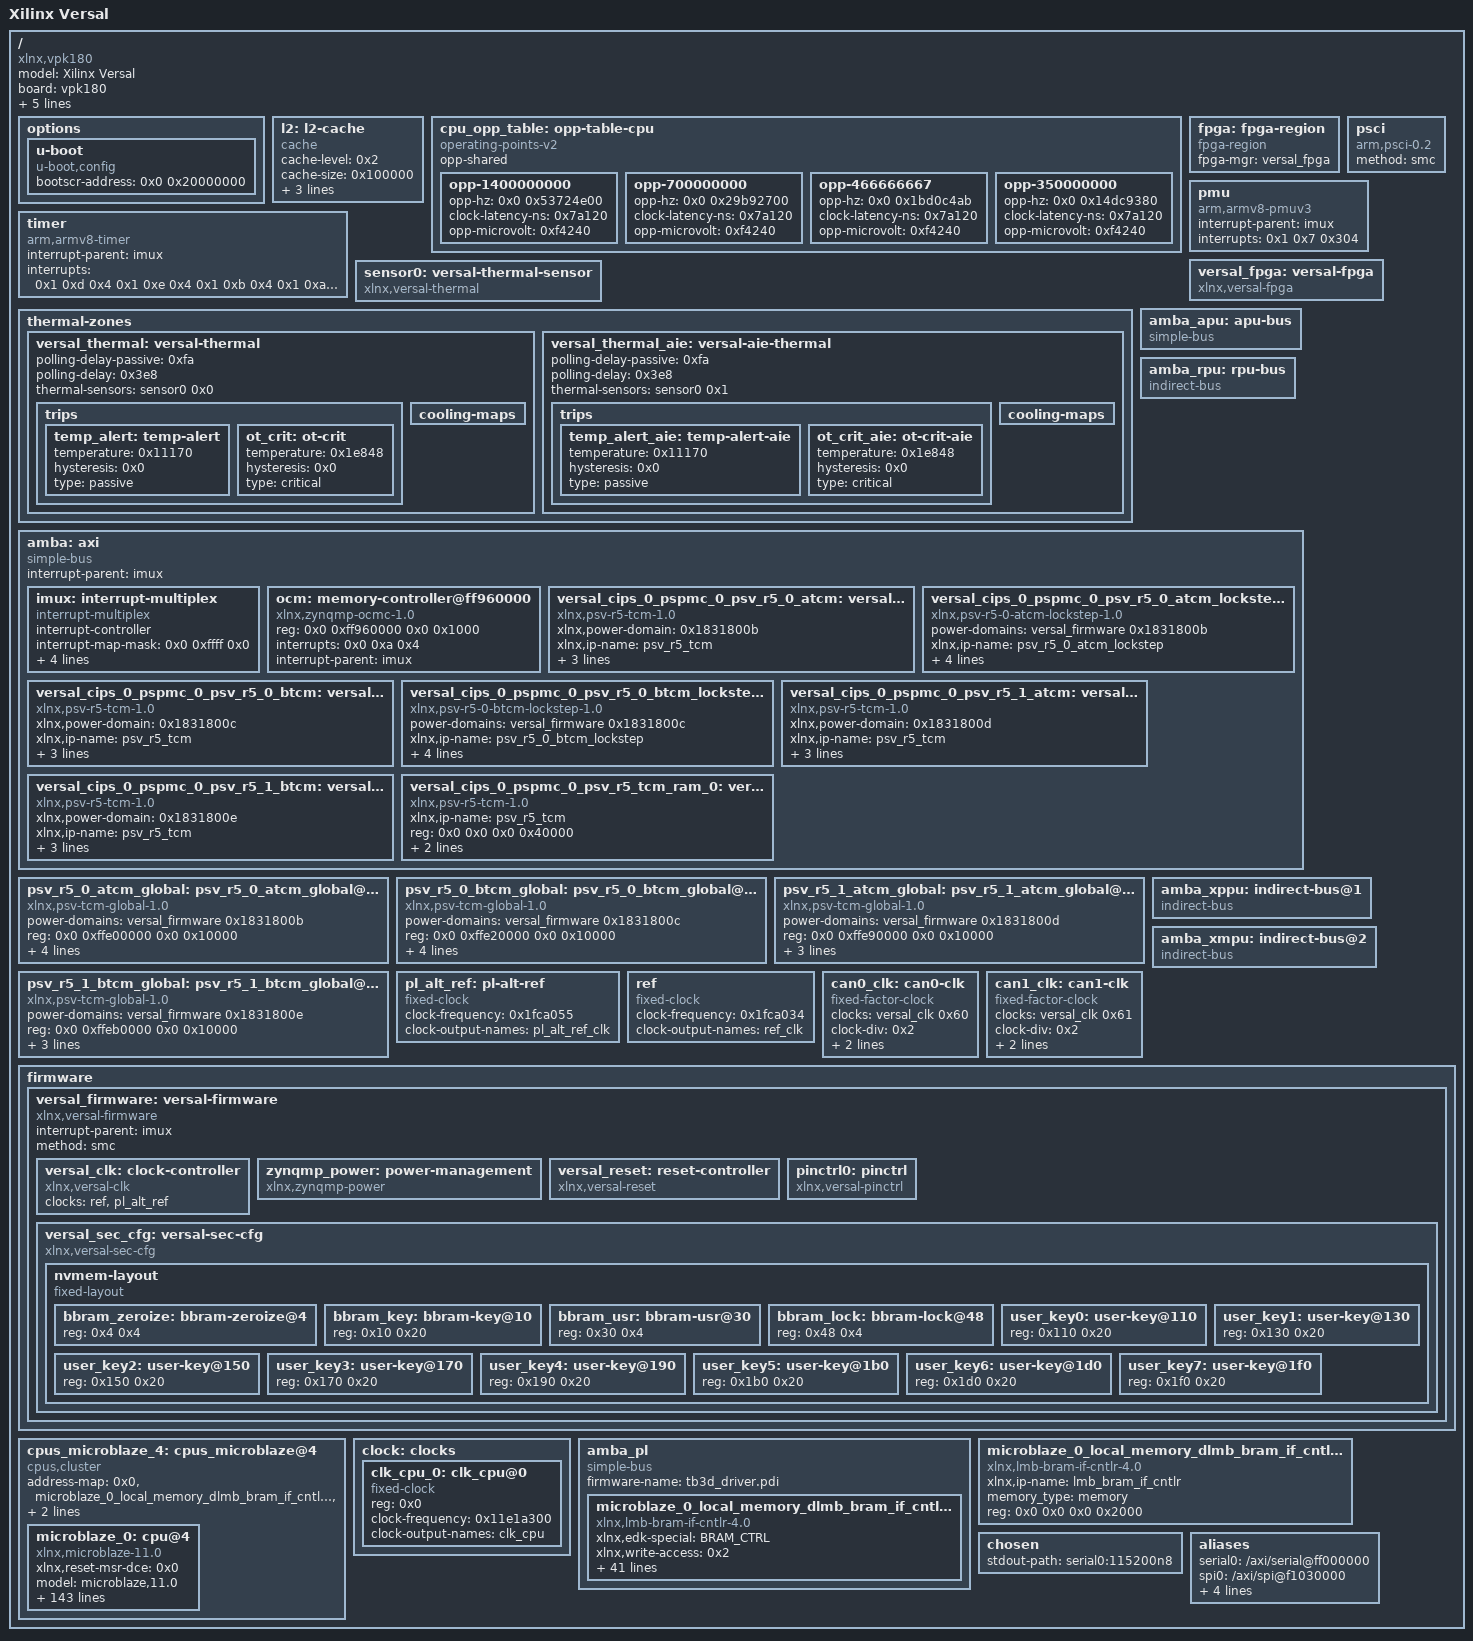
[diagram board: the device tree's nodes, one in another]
/dts-v1/;
/ {
        compatible = "xlnx,vpk180";
        #address-cells = <0x2>;
        #size-cells = <0x2>;
        model = "Xilinx Versal";
        board = "vpk180";
        device_id = "xcvp1802";
        slrcount = <0x4>;
        family = "Versal";
        speed_grade = "2MP";
        pruned-sdt = <0x1>;

        options {

                u-boot {
                        compatible = "u-boot,config";
                        bootscr-address = <0x0 0x20000000>;
                };
        };

        l2: l2-cache {
                phandle = <0x87>;
                compatible = "cache";
                cache-level = <0x2>;
                cache-size = <0x100000>;
                cache-line-size = <0x40>;
                cache-sets = <0x1000>;
                cache-unified;
        };

        cpu_opp_table: opp-table-cpu {
                phandle = <0x84>;
                compatible = "operating-points-v2";
                opp-shared;

                opp-1400000000 {
                        opp-hz = <0x0 0x53724e00>;
                        clock-latency-ns = <0x7a120>;
                        opp-microvolt = <0xf4240>;
                };

                opp-700000000 {
                        opp-hz = <0x0 0x29b92700>;
                        clock-latency-ns = <0x7a120>;
                        opp-microvolt = <0xf4240>;
                };

                opp-466666667 {
                        opp-hz = <0x0 0x1bd0c4ab>;
                        clock-latency-ns = <0x7a120>;
                        opp-microvolt = <0xf4240>;
                };

                opp-350000000 {
                        opp-hz = <0x0 0x14dc9380>;
                        clock-latency-ns = <0x7a120>;
                        opp-microvolt = <0xf4240>;
                };
        };

        fpga: fpga-region {
                phandle = <0xb6>;
                compatible = "fpga-region";
                fpga-mgr = <&versal_fpga>;
                #address-cells = <0x2>;
                #size-cells = <0x2>;
        };

        psci: psci {
                phandle = <0xb7>;
                compatible = "arm,psci-0.2";
                method = "smc";
        };

        pmu {
                compatible = "arm,armv8-pmuv3";
                interrupt-parent = <&imux>;
                interrupts = <0x1 0x7 0x304>;
        };

        timer: timer {
                phandle = <0xb8>;
                compatible = "arm,armv8-timer";
                interrupt-parent = <&imux>;
                interrupts = <0x1 0xd 0x4 0x1 0xe 0x4 0x1 0xb 0x4 0x1 0xa 0x4>;
        };

        versal_fpga: versal-fpga {
                phandle = <0x9d>;
                compatible = "xlnx,versal-fpga";
        };

        sensor0: versal-thermal-sensor {
                phandle = <0x9f>;
                compatible = "xlnx,versal-thermal";
                #thermal-sensor-cells = <0x1>;
                io-channel-names = "sysmon-temp-channel";
        };

        thermal-zones {

                versal_thermal: versal-thermal {
                        phandle = <0xb9>;
                        polling-delay-passive = <0xfa>;
                        polling-delay = <0x3e8>;
                        thermal-sensors = <&sensor0 0x0>;

                        trips {

                                temp_alert: temp-alert {
                                        phandle = <0xba>;
                                        temperature = <0x11170>;
                                        hysteresis = <0x0>;
                                        type = "passive";
                                };

                                ot_crit: ot-crit {
                                        phandle = <0xbb>;
                                        temperature = <0x1e848>;
                                        hysteresis = <0x0>;
                                        type = "critical";
                                };
                        };

                        cooling-maps {
                        };
                };

                versal_thermal_aie: versal-aie-thermal {
                        phandle = <0xbc>;
                        polling-delay-passive = <0xfa>;
                        polling-delay = <0x3e8>;
                        thermal-sensors = <&sensor0 0x1>;

                        trips {

                                temp_alert_aie: temp-alert-aie {
                                        phandle = <0xbd>;
                                        temperature = <0x11170>;
                                        hysteresis = <0x0>;
                                        type = "passive";
                                };

                                ot_crit_aie: ot-crit-aie {
                                        phandle = <0xbe>;
                                        temperature = <0x1e848>;
                                        hysteresis = <0x0>;
                                        type = "critical";
                                };
                        };

                        cooling-maps {
                        };
                };
        };

        amba_apu: apu-bus {
                phandle = <0x2>;
                compatible = "simple-bus";
                #address-cells = <0x2>;
                #size-cells = <0x2>;
                ranges;
                bootph-all;
        };

        amba_rpu: rpu-bus {
                phandle = <0x92>;
                compatible = "indirect-bus";
                #address-cells = <0x2>;
                #size-cells = <0x2>;
                ranges;
                bootph-all;
        };

        amba: axi {
                phandle = <0x1>;
                compatible = "simple-bus";
                #address-cells = <0x2>;
                #size-cells = <0x2>;
                ranges;
                interrupt-parent = <&imux>;
                bootph-all;

                imux: interrupt-multiplex {
                        phandle = <0x9e>;
                        compatible = "interrupt-multiplex";
                        #address-cells = <0x0>;
                        #interrupt-cells = <0x3>;
                        interrupt-controller;
                        interrupt-map-mask = <0x0 0xffff 0x0>;
                        interrupt-map = <0x58 0x0 0x15 &amba 0x0>,
                         <0x0 0x58 0x0 &psv_r5_1_btcm_global 0x4>,
                         <0x96 0x0 0x14 &amba 0x0>,
                         <0x83 0x4 0x0 &cpu_opp_table 0x0>;
                };

                ocm: memory-controller@ff960000 {
                        phandle = <0xc9>;
                        compatible = "xlnx,zynqmp-ocmc-1.0";
                        reg = <0x0 0xff960000 0x0 0x1000>;
                        interrupts = <0x0 0xa 0x4>;
                        interrupt-parent = <&imux>;
                };

                versal_cips_0_pspmc_0_psv_r5_0_atcm: versal_cips_0_pspmc_0_psv_r5_0_atcm@0 {
                        phandle = <0x93>;
                        xlnx,power-domain = <0x1831800b>;
                        compatible = "xlnx,psv-r5-tcm-1.0";
                        status = "okay";
                        xlnx,ip-name = "psv_r5_tcm";
                        xlnx,bank-size = <0x10000>;
                        reg = <0x0 0x0 0x0 0x10000>;
                        xlnx,name = "versal_cips_0_pspmc_0_psv_r5_0_atcm";
                };

                versal_cips_0_pspmc_0_psv_r5_0_atcm_lockstep: versal_cips_0_pspmc_0_psv_r5_0_atcm_lockstep@ffe10000 {
                        phandle = <0x148>;
                        compatible = "xlnx,psv-r5-0-atcm-lockstep-1.0", "mmio-sram";
                        status = "okay";
                        power-domains = <&versal_firmware 0x1831800b>;
                        xlnx,ip-name = "psv_r5_0_atcm_lockstep";
                        xlnx,is-hierarchy;
                        reg = <0x0 0xffe10000 0x0 0x10000>;
                        xlnx,name = "versal_cips_0_pspmc_0_psv_r5_0_atcm_lockstep";
                };

                versal_cips_0_pspmc_0_psv_r5_0_btcm: versal_cips_0_pspmc_0_psv_r5_0_btcm@20000 {
                        phandle = <0x95>;
                        xlnx,power-domain = <0x1831800c>;
                        compatible = "xlnx,psv-r5-tcm-1.0";
                        status = "okay";
                        xlnx,ip-name = "psv_r5_tcm";
                        xlnx,bank-size = <0x10000>;
                        reg = <0x0 0x20000 0x0 0x10000>;
                        xlnx,name = "versal_cips_0_pspmc_0_psv_r5_0_btcm";
                };

                versal_cips_0_pspmc_0_psv_r5_0_btcm_lockstep: versal_cips_0_pspmc_0_psv_r5_0_btcm_lockstep@ffe30000 {
                        phandle = <0x149>;
                        compatible = "xlnx,psv-r5-0-btcm-lockstep-1.0", "mmio-sram";
                        status = "okay";
                        power-domains = <&versal_firmware 0x1831800c>;
                        xlnx,ip-name = "psv_r5_0_btcm_lockstep";
                        xlnx,is-hierarchy;
                        reg = <0x0 0xffe30000 0x0 0x10000>;
                        xlnx,name = "versal_cips_0_pspmc_0_psv_r5_0_btcm_lockstep";
                };

                versal_cips_0_pspmc_0_psv_r5_1_atcm: versal_cips_0_pspmc_0_psv_r5_1_atcm@0 {
                        phandle = <0x9b>;
                        xlnx,power-domain = <0x1831800d>;
                        compatible = "xlnx,psv-r5-tcm-1.0";
                        status = "okay";
                        xlnx,ip-name = "psv_r5_tcm";
                        xlnx,bank-size = <0x10000>;
                        reg = <0x0 0x0 0x0 0x10000>;
                        xlnx,name = "versal_cips_0_pspmc_0_psv_r5_1_atcm";
                };

                versal_cips_0_pspmc_0_psv_r5_1_btcm: versal_cips_0_pspmc_0_psv_r5_1_btcm@20000 {
                        phandle = <0x9c>;
                        xlnx,power-domain = <0x1831800e>;
                        compatible = "xlnx,psv-r5-tcm-1.0";
                        status = "okay";
                        xlnx,ip-name = "psv_r5_tcm";
                        xlnx,bank-size = <0x10000>;
                        reg = <0x0 0x20000 0x0 0x10000>;
                        xlnx,name = "versal_cips_0_pspmc_0_psv_r5_1_btcm";
                };

                versal_cips_0_pspmc_0_psv_r5_tcm_ram_0: versal_cips_0_pspmc_0_psv_r5_tcm_ram_0@0 {
                        phandle = <0x94>;
                        compatible = "xlnx,psv-r5-tcm-1.0";
                        status = "okay";
                        xlnx,ip-name = "psv_r5_tcm";
                        reg = <0x0 0x0 0x0 0x40000>;
                        xlnx,name = "versal_cips_0_pspmc_0_psv_r5_tcm_ram_0";
                };
        };

        psv_r5_0_atcm_global: psv_r5_0_atcm_global@ffe00000 {
                phandle = <0x81>;
                compatible = "xlnx,psv-tcm-global-1.0", "mmio-sram";
                power-domains = <&versal_firmware 0x1831800b>;
                reg = <0x0 0xffe00000 0x0 0x10000>;
                status = "okay";
                xlnx,ip-name = "psv_tcm_global";
                xlnx,is-hierarchy;
                xlnx,name = "versal_cips_0_pspmc_0_psv_r5_0_atcm_global";
        };

        psv_r5_0_btcm_global: psv_r5_0_btcm_global@ffe20000 {
                phandle = <0x14a>;
                compatible = "xlnx,psv-tcm-global-1.0", "mmio-sram";
                power-domains = <&versal_firmware 0x1831800c>;
                reg = <0x0 0xffe20000 0x0 0x10000>;
                status = "okay";
                xlnx,ip-name = "psv_tcm_global";
                xlnx,is-hierarchy;
                xlnx,name = "versal_cips_0_pspmc_0_psv_r5_0_btcm_global";
        };

        psv_r5_1_atcm_global: psv_r5_1_atcm_global@ffe90000 {
                phandle = <0x82>;
                compatible = "xlnx,psv-tcm-global-1.0", "mmio-sram";
                power-domains = <&versal_firmware 0x1831800d>;
                reg = <0x0 0xffe90000 0x0 0x10000>;
                status = "okay";
                xlnx,ip-name = "psv_tcm_global";
                xlnx,name = "versal_cips_0_pspmc_0_psv_r5_1_atcm_global";
        };

        psv_r5_1_btcm_global: psv_r5_1_btcm_global@ffeb0000 {
                phandle = <0x83>;
                compatible = "xlnx,psv-tcm-global-1.0", "mmio-sram";
                power-domains = <&versal_firmware 0x1831800e>;
                reg = <0x0 0xffeb0000 0x0 0x10000>;
                status = "okay";
                xlnx,ip-name = "psv_tcm_global";
                xlnx,name = "versal_cips_0_pspmc_0_psv_r5_1_btcm_global";
        };

        amba_xppu: indirect-bus@1 {
                phandle = <0x14b>;
                compatible = "indirect-bus";
                #address-cells = <0x2>;
                #size-cells = <0x2>;
        };

        amba_xmpu: indirect-bus@2 {
                phandle = <0x14c>;
                compatible = "indirect-bus";
                #address-cells = <0x2>;
                #size-cells = <0x2>;
        };

        pl_alt_ref: pl-alt-ref {
                phandle = <0xa6>;
                bootph-all;
                compatible = "fixed-clock";
                #clock-cells = <0x0>;
                clock-frequency = <0x1fca055>;
                clock-output-names = "pl_alt_ref_clk";
        };

        ref: ref {
                phandle = <0xa5>;
                bootph-all;
                compatible = "fixed-clock";
                #clock-cells = <0x0>;
                clock-frequency = <0x1fca034>;
                clock-output-names = "ref_clk";
        };

        can0_clk: can0-clk {
                phandle = <0xa0>;
                #clock-cells = <0x0>;
                compatible = "fixed-factor-clock";
                clocks = <&versal_clk 0x60>;
                clock-div = <0x2>;
                clock-mult = <0x1>;
                clock-output-names = "can0_clk";
        };

        can1_clk: can1-clk {
                phandle = <0xa1>;
                #clock-cells = <0x0>;
                compatible = "fixed-factor-clock";
                clocks = <&versal_clk 0x61>;
                clock-div = <0x2>;
                clock-mult = <0x1>;
                clock-output-names = "can1_clk";
        };

        firmware {

                versal_firmware: versal-firmware {
                        phandle = <0x86>;
                        compatible = "xlnx,versal-firmware";
                        interrupt-parent = <&imux>;
                        bootph-all;
                        method = "smc";
                        #power-domain-cells = <0x1>;

                        versal_clk: clock-controller {
                                phandle = <0x88>;
                                bootph-all;
                                #clock-cells = <0x1>;
                                compatible = "xlnx,versal-clk";
                                clocks = <&ref>,
                                 <&pl_alt_ref>;
                                clock-names = "ref", "pl_alt_ref";
                        };

                        zynqmp_power: power-management {
                                phandle = <0x151>;
                                compatible = "xlnx,zynqmp-power";
                        };

                        versal_reset: reset-controller {
                                phandle = <0xa2>;
                                compatible = "xlnx,versal-reset";
                                #reset-cells = <0x1>;
                        };

                        pinctrl0: pinctrl {
                                phandle = <0x152>;
                                compatible = "xlnx,versal-pinctrl";
                        };

                        versal_sec_cfg: versal-sec-cfg {
                                phandle = <0x153>;
                                compatible = "xlnx,versal-sec-cfg";

                                nvmem-layout {
                                        compatible = "fixed-layout";
                                        #address-cells = <0x1>;
                                        #size-cells = <0x1>;

                                        bbram_zeroize: bbram-zeroize@4 {
                                                phandle = <0x154>;
                                                reg = <0x4 0x4>;
                                        };

                                        bbram_key: bbram-key@10 {
                                                phandle = <0x155>;
                                                reg = <0x10 0x20>;
                                        };

                                        bbram_usr: bbram-usr@30 {
                                                phandle = <0x156>;
                                                reg = <0x30 0x4>;
                                        };

                                        bbram_lock: bbram-lock@48 {
                                                phandle = <0x157>;
                                                reg = <0x48 0x4>;
                                        };

                                        user_key0: user-key@110 {
                                                phandle = <0x158>;
                                                reg = <0x110 0x20>;
                                        };

                                        user_key1: user-key@130 {
                                                phandle = <0x159>;
                                                reg = <0x130 0x20>;
                                        };

                                        user_key2: user-key@150 {
                                                phandle = <0x15a>;
                                                reg = <0x150 0x20>;
                                        };

                                        user_key3: user-key@170 {
                                                phandle = <0x15b>;
                                                reg = <0x170 0x20>;
                                        };

                                        user_key4: user-key@190 {
                                                phandle = <0x15c>;
                                                reg = <0x190 0x20>;
                                        };

                                        user_key5: user-key@1b0 {
                                                phandle = <0x15d>;
                                                reg = <0x1b0 0x20>;
                                        };

                                        user_key6: user-key@1d0 {
                                                phandle = <0x15e>;
                                                reg = <0x1d0 0x20>;
                                        };

                                        user_key7: user-key@1f0 {
                                                phandle = <0x15f>;
                                                reg = <0x1f0 0x20>;
                                        };
                                };
                        };
                };
        };

        cpus_microblaze_4: cpus_microblaze@4 {
                phandle = <0x160>;
                #cpu-mask-cells = <0x1>;
                compatible = "cpus,cluster";
                #address-cells = <0x1>;
                #size-cells = <0x0>;
                address-map = <0x0 &microblaze_0_local_memory_dlmb_bram_if_cntlr_memory 0x0 0x2000>,
                 <0x0 &microblaze_0_local_memory_dlmb_bram_if_cntlr 0x0 0x2000>;
                #ranges-address-cells = <0x1>;
                #ranges-size-cells = <0x1>;

                microblaze_0: cpu@4 {
                        phandle = <0x161>;
                        xlnx,reset-msr-dce = <0x0>;
                        model = "microblaze,11.0";
                        xlnx,addr-tag-bits = <0x0>;
                        xlnx,d-axi = <0x0>;
                        xlnx,interrupt-mon = <0x0>;
                        xlnx,iaddr-size = <0x20>;
                        xlnx,number-of-wr-addr-brk = <0x1>;
                        xlnx,dynamic-bus-sizing = <0x0>;
                        xlnx,temporal-depth = <0x0>;
                        xlnx,use-interrupt = <0x0>;
                        xlnx,optimization = <0x0>;
                        xlnx,ip-axi-mon = <0x0>;
                        xlnx,ip-name = "microblaze";
                        d-cache-highaddr = <0x3fffffff>;
                        xlnx,dcache-force-tag-lutram = <0x0>;
                        xlnx,pc-width = <0x20>;
                        xlnx,interrupt-is-edge = <0x0>;
                        reg = <0x4>;
                        xlnx,async-interrupt = <0x1>;
                        xlnx,use-mmu = <0x3>;
                        xlnx,reset-msr-ee = <0x0>;
                        xlnx,icache-victims = <0x0>;
                        xlnx,use-reorder-instr = <0x1>;
                        xlnx,d-lmb-mon = <0x0>;
                        xlnx,d-lmb-protocol = <0x0>;
                        xlnx,ill-opcode-exception = <0x0>;
                        xlnx,dcache-always-used = <0x1>;
                        xlnx,use-div = <0x0>;
                        xlnx,dc-axi-mon = <0x0>;
                        xlnx,debug-trace-async-reset = <0x0>;
                        xlnx,trace = <0x0>;
                        xlnx,part = "xcvp1802-lsvc4072-2mp-e-s";
                        i-cache-baseaddr = <0x0>;
                        xlnx,use-config-reset = <0x0>;
                        xlnx,pvr = <0x0>;
                        xlnx,i-lmb-mon = <0x0>;
                        xlnx,dcache-byte-size = <0x2000>;
                        xlnx,fault-tolerant = <0x0>;
                        xlnx,family = "versal";
                        compatible = "xlnx,microblaze-11.0", "xlnx,microblaze";
                        xlnx,data-size = <0x40>;
                        xlnx,mmu-zones = <0x10>;
                        xlnx,debug-trace-size = <0x2000>;
                        xlnx,mmu-privileged-instr = <0x0>;
                        xlnx,enable-discrete-ports = <0x0>;
                        d-cache-line-size = <0x10>;
                        xlnx,d-lmb = <0x1>;
                        xlnx,sco = <0x0>;
                        xlnx,reset-msr-eip = <0x0>;
                        xlnx,debug-interface = <0x0>;
                        clock-frequency = <0x11e1a300>;
                        xlnx,use-ext-brk = <0x0>;
                        xlnx,daddr-size = <0x20>;
                        xlnx,debug-enabled = <0x0>;
                        xlnx,reset-msr-ice = <0x0>;
                        xlnx,num-sync-ff-dbg-trace-clk = <0x2>;
                        xlnx,i-lmb-protocol = <0x0>;
                        xlnx,endianness = <0x1>;
                        xlnx,fsl-exception = <0x0>;
                        i-cache-line-size = <0x10>;
                        xlnx,use-extended-fsl-instr = <0x0>;
                        xlnx,reset-msr = <0x0>;
                        xlnx,dp-axi-mon = <0x0>;
                        device_type = "cpu";
                        xlnx,branch-target-cache-size = <0x0>;
                        xlnx,dcache-use-writeback = <0x0>;
                        xlnx,div-zero-exception = <0x0>;
                        xlnx,mmu-tlb-access = <0x3>;
                        bus-handle = <&amba_pl>;
                        xlnx,cache-byte-size = <0x2000>;
                        xlnx,pvr-user2 = <0x0>;
                        xlnx,opcode-0x0-illegal = <0x0>;
                        xlnx,icache-line-len = <0x4>;
                        xlnx,ecc-use-ce-exception = <0x0>;
                        xlnx,base-vectors = <0x0>;
                        xlnx,d-lmb-has-prot = <0x0>;
                        xlnx,edk-special = "microblaze";
                        xlnx,use-dcache = <0x0>;
                        xlnx,use-barrel = <0x0>;
                        xlnx,reset-msr-bip = <0x0>;
                        xlnx,allow-dcache-wr = <0x1>;
                        xlnx,debug-external-trace = <0x0>;
                        xlnx,addr-size = <0x20>;
                        xlnx,piaddr-size = <0x20>;
                        i-cache-highaddr = <0x3fffffff>;
                        xlnx,num-sync-ff-clk-debug = <0x2>;
                        xlnx,debug-event-counters = <0x5>;
                        xlnx,fpu-exception = <0x0>;
                        xlnx,allow-icache-wr = <0x1>;
                        xlnx,g-use-exceptions = <0x0>;
                        xlnx,i-axi = <0x0>;
                        xlnx,g-template-list = <0x0>;
                        xlnx,icache-streams = <0x0>;
                        xlnx,dcache-line-len = <0x4>;
                        xlnx,num-sync-ff-clk = <0x2>;
                        xlnx,edk-iptype = "PROCESSOR";
                        xlnx,use-stack-protection = <0x0>;
                        xlnx,use-hw-mul = <0x0>;
                        xlnx,num-sync-ff-dbg-clk = <0x1>;
                        xlnx,interconnect = <0x2>;
                        xlnx,i-lmb-has-prot = <0x0>;
                        xlnx,debug-latency-counters = <0x1>;
                        i-cache-size = <0x2000>;
                        xlnx,exceptions-in-delay-slots = <0x1>;
                        xlnx,use-fpu = <0x0>;
                        xlnx,reset-msr-ie = <0x0>;
                        xlnx,edge-is-positive = <0x1>;
                        xlnx,use-pcmp-instr = <0x1>;
                        xlnx,use-icache = <0x0>;
                        d-cache-size = <0x2000>;
                        xlnx,memory-ip-list = "microblaze_0_local_memory_ilmb_bram_if_cntlr_memory", "microblaze_0_local_memory_dlmb_bram_if_cntlr_memory";
                        xlnx,async-wakeup = <0x3>;
                        xlnx,use-non-secure = <0x0>;
                        xlnx,dcache-addr-tag = <0x0>;
                        xlnx,number-of-rd-addr-brk = <0x0>;
                        d-cache-baseaddr = <0x0>;
                        xlnx,area-optimized = <0x2>;
                        xlnx,avoid-primitives = <0x0>;
                        xlnx,lockstep-slave = <0x0>;
                        xlnx,use-ext-nm-brk = <0x0>;
                        xlnx,instr-size = <0x20>;
                        xlnx,icache-always-used = <0x1>;
                        xlnx,i-lmb = <0x1>;
                        xlnx,mmu-dtlb-size = <0x4>;
                        xlnx,lockstep-select = <0x0>;
                        xlnx,lmb-data-size = <0x20>;
                        xlnx,ic-axi-mon = <0x0>;
                        xlnx,enable-conversion = <0x0>;
                        xlnx,num-sync-ff-clk-irq = <0x1>;
                        xlnx,fsl-links = <0x0>;
                        timebase-frequency = <0x11e1a300>;
                        xlnx,icache-force-tag-lutram = <0x0>;
                        xlnx,dcache-data-width = <0x0>;
                        xlnx,dcache-victims = <0x0>;
                        xlnx,use-branch-target-cache = <0x1>;
                        xlnx,debug-profile-size = <0x0>;
                        xlnx,unaligned-exceptions = <0x0>;
                        xlnx,lockstep-master = <0x0>;
                        xlnx,freq = <0x11e1a300>;
                        xlnx,number-of-pc-brk = <0x1>;
                        xlnx,mmu-itlb-size = <0x2>;
                        xlnx,imprecise-exceptions = <0x0>;
                        xlnx,use-msr-instr = <0x0>;
                        xlnx,icache-data-width = <0x0>;
                        xlnx,debug-counter-width = <0x20>;
                };
        };

        clock: clocks {
                phandle = <0x162>;
                #address-cells = <0x1>;
                #size-cells = <0x0>;

                clk_cpu_0: clk_cpu@0 {
                        phandle = <0x163>;
                        compatible = "fixed-clock";
                        reg = <0x0>;
                        clock-frequency = <0x11e1a300>;
                        clock-output-names = "clk_cpu";
                        #clock-cells = <0x0>;
                };
        };

        amba_pl: amba_pl {
                phandle = <0xa9>;
                ranges;
                compatible = "simple-bus";
                #address-cells = <0x2>;
                #size-cells = <0x2>;
                firmware-name = "tb3d_driver.pdi";

                microblaze_0_local_memory_dlmb_bram_if_cntlr: lmb_bram_if_cntlr@0 {
                        phandle = <0xa8>;
                        xlnx,edk-special = "BRAM_CTRL";
                        xlnx,write-access = <0x2>;
                        compatible = "xlnx,lmb-bram-if-cntlr-4.0", "xlnx,axi-bram-ctrl";
                        xlnx,ecc-onoff-register = <0x0>;
                        xlnx,ecc-onoff-reset-value = <0x1>;
                        xlnx,s-axi-ctrl-protocol = "AXI4LITE";
                        xlnx,mask = <0x0>;
                        xlnx,mask1 = <0x800000>;
                        xlnx,mask2 = <0x800000>;
                        xlnx,fault-inject = <0x0>;
                        xlnx,mask3 = <0x800000>;
                        xlnx,ip-name = "lmb_bram_if_cntlr";
                        xlnx,arbitration = <0x0>;
                        xlnx,num-lmb = <0x1>;
                        xlnx,mask4 = <0x800000>;
                        reg = <0x0 0x0 0x0 0x2000>;
                        xlnx,s-axi-ctrl-addr-width = <0x20>;
                        xlnx,mask5 = <0x800000>;
                        xlnx,ecc-status-registers = <0x0>;
                        xlnx,prot-cfg = <0xff>;
                        xlnx,mask6 = <0x800000>;
                        xlnx,lmb-protocol = <0x0>;
                        xlnx,ce-counter-width = <0x0>;
                        xlnx,prot-cfg1 = <0xff>;
                        xlnx,mask7 = <0x800000>;
                        xlnx,ecc = <0x0>;
                        xlnx,edk-iptype = "PERIPHERAL";
                        xlnx,prot-cfg2 = <0xff>;
                        xlnx,lmb-dwidth = <0x20>;
                        xlnx,interconnect = <0x0>;
                        xlnx,ce-failing-registers = <0x0>;
                        xlnx,prot-cfg3 = <0xff>;
                        xlnx,ue-failing-registers = <0x0>;
                        xlnx,prot-cfg4 = <0xff>;
                        xlnx,lmb-has-prot = <0x0>;
                        status = "okay";
                        xlnx,data-width = <0x20>;
                        xlnx,prot-cfg5 = <0xff>;
                        xlnx,s-axi-ctrl-data-width = <0x20>;
                        xlnx,prot-cfg6 = <0xff>;
                        xlnx,bram-awidth = <0x20>;
                        xlnx,prot-cfg7 = <0xff>;
                        xlnx,lmb-awidth = <0x24>;
                        xlnx,name = "microblaze_0_local_memory_dlmb_bram_if_cntlr";
                };
        };

        microblaze_0_local_memory_dlmb_bram_if_cntlr_memory: memory@0 {
                phandle = <0xa7>;
                compatible = "xlnx,lmb-bram-if-cntlr-4.0";
                xlnx,ip-name = "lmb_bram_if_cntlr";
                device_type = "memory";
                memory_type = "memory";
                reg = <0x0 0x0 0x0 0x2000>;
        };

        chosen {
                stdout-path = "serial0:115200n8";
        };

        aliases {
                serial0 = "/axi/serial@ff000000";
                spi0 = "/axi/spi@f1030000";
                serial1 = "/axi/coresight@f0800000";
                i2c0 = "/axi/i2c@ff020000";
                i2c1 = "/axi/i2c@ff030000";
                ethernet0 = "/axi/ethernet@ff0c0000";
        };

        __symbols__ {
                l2 = "/l2-cache";
                cpu_opp_table = "/opp-table-cpu";
                fpga = "/fpga-region";
                psci = "/psci";
                timer = "/timer";
                versal_fpga = "/versal-fpga";
                sensor0 = "/versal-thermal-sensor";
                versal_thermal = "/thermal-zones/versal-thermal";
                temp_alert = "/thermal-zones/versal-thermal/trips/temp-alert";
                ot_crit = "/thermal-zones/versal-thermal/trips/ot-crit";
                versal_thermal_aie = "/thermal-zones/versal-aie-thermal";
                temp_alert_aie = "/thermal-zones/versal-aie-thermal/trips/temp-alert-aie";
                ot_crit_aie = "/thermal-zones/versal-aie-thermal/trips/ot-crit-aie";
                amba_apu = "/apu-bus";
                amba_rpu = "/rpu-bus";
                amba = "/axi";
                imux = "/axi/interrupt-multiplex";
                ocm = "/axi/memory-controller@ff960000";
                versal_cips_0_pspmc_0_psv_r5_0_atcm = "/axi/versal_cips_0_pspmc_0_psv_r5_0_atcm@0";
                versal_cips_0_pspmc_0_psv_r5_0_atcm_lockstep = "/axi/versal_cips_0_pspmc_0_psv_r5_0_atcm_lockstep@ffe10000";
                versal_cips_0_pspmc_0_psv_r5_0_btcm = "/axi/versal_cips_0_pspmc_0_psv_r5_0_btcm@20000";
                versal_cips_0_pspmc_0_psv_r5_0_btcm_lockstep = "/axi/versal_cips_0_pspmc_0_psv_r5_0_btcm_lockstep@ffe30000";
                versal_cips_0_pspmc_0_psv_r5_1_atcm = "/axi/versal_cips_0_pspmc_0_psv_r5_1_atcm@0";
                versal_cips_0_pspmc_0_psv_r5_1_btcm = "/axi/versal_cips_0_pspmc_0_psv_r5_1_btcm@20000";
                versal_cips_0_pspmc_0_psv_r5_tcm_ram_0 = "/axi/versal_cips_0_pspmc_0_psv_r5_tcm_ram_0@0";
                psv_r5_0_atcm_global = "/psv_r5_0_atcm_global@ffe00000";
                psv_r5_0_btcm_global = "/psv_r5_0_btcm_global@ffe20000";
                psv_r5_1_atcm_global = "/psv_r5_1_atcm_global@ffe90000";
                psv_r5_1_btcm_global = "/psv_r5_1_btcm_global@ffeb0000";
                amba_xppu = "/indirect-bus@1";
                amba_xmpu = "/indirect-bus@2";
                pl_alt_ref = "/pl-alt-ref";
                ref = "/ref";
                can0_clk = "/can0-clk";
                can1_clk = "/can1-clk";
                versal_firmware = "/firmware/versal-firmware";
                versal_clk = "/firmware/versal-firmware/clock-controller";
                zynqmp_power = "/firmware/versal-firmware/power-management";
                versal_reset = "/firmware/versal-firmware/reset-controller";
                pinctrl0 = "/firmware/versal-firmware/pinctrl";
                versal_sec_cfg = "/firmware/versal-firmware/versal-sec-cfg";
                bbram_zeroize = "/firmware/versal-firmware/versal-sec-cfg/nvmem-layout/bbram-zeroize@4";
                bbram_key = "/firmware/versal-firmware/versal-sec-cfg/nvmem-layout/bbram-key@10";
                bbram_usr = "/firmware/versal-firmware/versal-sec-cfg/nvmem-layout/bbram-usr@30";
                bbram_lock = "/firmware/versal-firmware/versal-sec-cfg/nvmem-layout/bbram-lock@48";
                user_key0 = "/firmware/versal-firmware/versal-sec-cfg/nvmem-layout/user-key@110";
                user_key1 = "/firmware/versal-firmware/versal-sec-cfg/nvmem-layout/user-key@130";
                user_key2 = "/firmware/versal-firmware/versal-sec-cfg/nvmem-layout/user-key@150";
                user_key3 = "/firmware/versal-firmware/versal-sec-cfg/nvmem-layout/user-key@170";
                user_key4 = "/firmware/versal-firmware/versal-sec-cfg/nvmem-layout/user-key@190";
                user_key5 = "/firmware/versal-firmware/versal-sec-cfg/nvmem-layout/user-key@1b0";
                user_key6 = "/firmware/versal-firmware/versal-sec-cfg/nvmem-layout/user-key@1d0";
                user_key7 = "/firmware/versal-firmware/versal-sec-cfg/nvmem-layout/user-key@1f0";
                cpus_microblaze_4 = "/cpus_microblaze@4";
                microblaze_0 = "/cpus_microblaze@4/cpu@4";
                clock = "/clocks";
                clk_cpu_0 = "/clocks/clk_cpu@0";
                amba_pl = "/amba_pl";
                microblaze_0_local_memory_dlmb_bram_if_cntlr = "/amba_pl/lmb_bram_if_cntlr@0";
                microblaze_0_local_memory_dlmb_bram_if_cntlr_memory = "/memory@0";
        };
};
